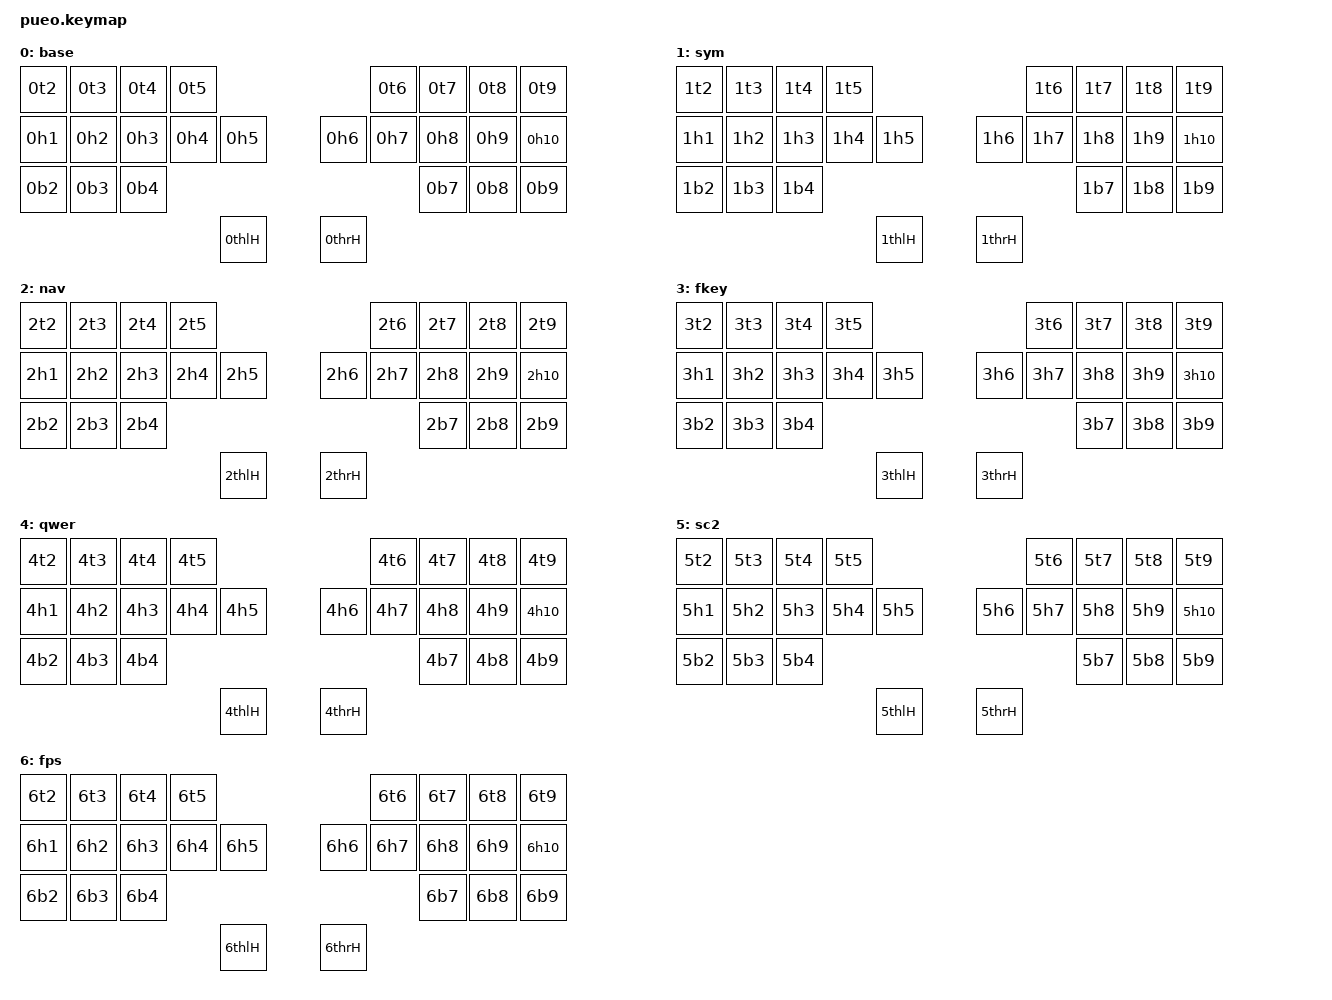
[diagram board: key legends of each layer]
#include "fingermap.h"

/ { 
behaviors { // -----------------------------------------------------------------------------------------------
        hml: home_row_mod_l { 		hold-trigger-key-positions = < 0 1 2 3 8 9 10 11 12 18 19 20 24 >; 		};
		hmr: home_row_mod_r { 		hold-trigger-key-positions = < 4 5 6 7 13 14 15 16 21 22 23 25 >; 	 }; };
// -----------------------------------------------------------------------------------------------------------

keymap { compatible = "zmk,keymap";
		zero 	{ display-name = "base"; // -------------------
		bindings = < _0t2 _0t3 _0t4 _0t5 		_0t6 _0t7 _0t8 _0t9
				_0h1 _0h2 _0h3 _0h4 _0h5 		_0h6 _0h7 _0h8 _0h9 _0h10
				   	 _0b2 _0b3 _0b4       		     _0b7 _0b8 _0b9
				         	   _0thlH	 		     _0thrH 		>; };
		one 	{ display-name = "sym"; // --------------------
		bindings = < _1t2 _1t3 _1t4 _1t5 		_1t6 _1t7 _1t8 _1t9
				_1h1 _1h2 _1h3 _1h4 _1h5 		_1h6 _1h7 _1h8 _1h9 _1h10
				   	 _1b2 _1b3 _1b4       		     _1b7 _1b8 _1b9
				         	   _1thlH	 		     _1thrH 		>; };
		two 	{ display-name = "nav"; // ------------------
		bindings = < _2t2 _2t3 _2t4 _2t5 		_2t6 _2t7 _2t8 _2t9
				_2h1 _2h2 _2h3 _2h4 _2h5 		_2h6 _2h7 _2h8 _2h9 _2h10
				   	 _2b2 _2b3 _2b4           		 _2b7 _2b8 _2b9
				         	   _2thlH	      		 _2thrH 		>; };
		three 	{ display-name = "fkey"; // -------------------
		bindings = < _3t2 _3t3 _3t4 _3t5 		_3t6 _3t7 _3t8 _3t9
				_3h1 _3h2 _3h3 _3h4 _3h5 		_3h6 _3h7 _3h8 _3h9 _3h10
				   	 _3b2 _3b3 _3b4           		 _3b7 _3b8 _3b9
				         	   _3thlH	      		 _3thrH 		>; };
		four 	{ display-name = "qwer"; // ----------------------
		bindings = < _4t2 _4t3 _4t4 _4t5 		_4t6 _4t7 _4t8 _4t9
				_4h1 _4h2 _4h3 _4h4 _4h5 		_4h6 _4h7 _4h8 _4h9 _4h10
				   	 _4b2 _4b3 _4b4           		 _4b7 _4b8 _4b9
				         	   _4thlH	      		 _4thrH 		>; };
		five 	{ display-name = "sc2"; // -----------------
		bindings = < _5t2 _5t3 _5t4 _5t5 		_5t6 _5t7 _5t8 _5t9
				_5h1 _5h2 _5h3 _5h4 _5h5 		_5h6 _5h7 _5h8 _5h9 _5h10
				   	 _5b2 _5b3 _5b4           		 _5b7 _5b8 _5b9
				         	   _5thlH	      		 _5thrH 		>; };
		six 	{ display-name = "fps"; // ------------------------
		bindings = < _6t2 _6t3 _6t4 _6t5 		_6t6 _6t7 _6t8 _6t9
				_6h1 _6h2 _6h3 _6h4 _6h5 		_6h6 _6h7 _6h8 _6h9 _6h10
				   	 _6b2 _6b3 _6b4           		 _6b7 _6b8 _6b9
				         	   _6thlH	      		 _6thrH 	 >; }; };

combos { compatible = "zmk,combos";
        // alphas ----------------------------------------------------------------------------------------------------------------------------------------
		cbo_x 				{ timeout-ms = <40>; 	key-positions = < 	9 18		>; 	bindings = <	&kp X				>;	layers = <	0		>; 	};
		cbo_q 				{ timeout-ms = <40>; 	key-positions = < 	10 19		>; 	bindings = <	&kp Q				>;	layers = <	0		>; 	};
		cbo_p 				{ timeout-ms = <40>; 	key-positions = < 	3 12		>; 	bindings = <	&kp P				>; 	layers = <	0		>; 	};
		cbo_z 				{ timeout-ms = <40>; 	key-positions = < 	4 13		>; 	bindings = <	&kp Z				>;	layers = <	0		>; 	};
		cbo_j 				{ timeout-ms = <40>; 	key-positions = < 	15 22		>; 	bindings = <	&kp J				>;	layers = <	0		>; 	};
		cbo_v 				{ timeout-ms = <40>; 	key-positions = < 	16 23		>; 	bindings = <	&kp V				>;	layers = <	0		>; 	};
		// symbols ---------------------------------------------------------------------------------------------------------------------------------------
		u_cbo_left 			{ timeout-ms = <40>; 	key-positions = < 	8 14		>; 	bindings = <	&uc 0x2190 0x2190	>; 	layers = <	1		>;	};
		u_cbo_up 			{ timeout-ms = <40>; 	key-positions = < 	10 15		>;	bindings = <	&uc 0x2191 0x2191	>; 	layers = <	1		>;	};
		u_cbo_down 			{ timeout-ms = <40>; 	key-positions = < 	9 16		>; 	bindings = <	&uc 0x2193 0x2193	>; 	layers = <	1		>;	};
		u_cbo_right 		{ timeout-ms = <40>; 	key-positions = < 	11 17		>; 	bindings = <	&uc 0x2192 0x2192	>;	layers = <	1		>;	};

		u_cbo_up_down		{ timeout-ms = <40>; 	key-positions = < 	1 6			>; 	bindings = <	&uc 0x2195 0x2195	>; 	layers = <	1		>;	};
		u_cbo_left_right	{ timeout-ms = <40>; 	key-positions = < 	8 17		>; 	bindings = <	&uc 0x2194 0x2194	>; 	layers = <	1		>;	};

		u_cbo_ne 			{ timeout-ms = <40>; 	key-positions = < 	2 7			>; 	bindings = <	&uc 0x2197 0x2197	>; 	layers = <	1		>;	};
		u_cbo_se 			{ timeout-ms = <40>; 	key-positions = < 	20 23		>; 	bindings = <	&uc 0x2198 0x2198	>; 	layers = <	1		>;	};
		u_cbo_sw 			{ timeout-ms = <40>; 	key-positions = < 	18 21		>; 	bindings = <	&uc 0x2199 0x2199	>; 	layers = <	1		>;	};
		u_cbo_nw 			{ timeout-ms = <40>; 	key-positions = < 	0 5			>; 	bindings = <	&uc 0x2196 0x2196	>; 	layers = <	1		>;	};

		u_cbo_skull 		{ timeout-ms = <40>; 	key-positions = < 	3 4 		>; 	bindings = <	&uc 0x2620 0x2620	>;	layers = <	1		>;	};
		u_cbo_frown 		{ timeout-ms = <40>; 	key-positions = < 	12 13 		>; 	bindings = <	&uc 0x2639 0x2639	>;	layers = <	1		>;	};
		// mods ------------------------------------------------------------------------------------------------------------------------------------------
		cbo_ctrl_l			{ timeout-ms = <20>; 	key-positions = < 	0 9			>; 	bindings = <	&sk LCTRL			>; 	layers = <	0 1 2 3	>; 	};
		cbo_gui_l			{ timeout-ms = <20>; 	key-positions = < 	1 10		>; 	bindings = <	&sk LGUI			>; 	layers = <	0 1 2 3	>; 	};
		cbo_shift_l  		{ timeout-ms = <20>; 	key-positions = < 	11 20		>; 	bindings = <	&sk LSHIFT			>;  layers = <	0 1 2 3	>; 	};
		cbo_alt_l			{ timeout-ms = <20>; 	key-positions = < 	3 12		>; 	bindings = <	&sk LALT			>; 	layers = <	0 1 2 3	>; 	};

		cbo_alt_r			{ timeout-ms = <20>; 	key-positions = < 	4 13		>; 	bindings = <	&sk LALT			>; 	layers = <	0 1 2 3	>; 	};
		cbo_shift_r			{ timeout-ms = <20>; 	key-positions = < 	14 21		>; 	bindings = <	&sk RSHIFT			>;  layers = <	0 1 2 3 >; 	};
		cbo_gui_r			{ timeout-ms = <20>; 	key-positions = < 	6 15		>; 	bindings = <	&sk RGUI			>; 	layers = <	0 1 2 3	>; 	};
		cbo_ctrl_r			{ timeout-ms = <20>; 	key-positions = < 	7 16		>; 	bindings = <	&sk RCTRL			>; 	layers = <	0 1 2 3	>; 	};

		cbo_back_l			{ timeout-ms = <20>; 	key-positions = < 	9 11		>; 	bindings = <	&amt LC(BSPC) BSPC	>; 	layers = <	0 1 2	>; 	};
		cbo_del_l			{ timeout-ms = <20>; 	key-positions = <	10 11		>; 	bindings = <	&amt LC(DEL) DEL	>; 	layers = <	0 1 2	>; 	};
		cbo_tab_l			{ timeout-ms = <20>; 	key-positions = <	0 2			>; 	bindings = <	&tabmt 0 TAB		>;	layers = <	0 1 2	>; 	};
		cbo_esc_l			{ timeout-ms = <20>; 	key-positions = < 	0 1 2		>; 	bindings = <	&amt LC(ESC) ESC	>;	layers = <	0 1 2	>; 	};
		cbo_enter_l			{ timeout-ms = <20>; 	key-positions = <	9 10		>; 	bindings = <	&amt LS(RET) RET	>; 	layers = <	0 1 2	>; 	};

		cbo_back_r			{ timeout-ms = <20>; 	key-positions = < 	14 15		>; 	bindings = <	&amt RC(BSPC) BSPC	>; 	layers = <	0 1 2	>; 	};
		cbo_del_r			{ timeout-ms = <20>; 	key-positions = < 	14 16		>; 	bindings = <	&amt RC(DEL) DEL	>; 	layers = <	0 1 2	>; 	};
		cbo_tab_r			{ timeout-ms = <20>; 	key-positions = < 	5 7			>;	bindings = <	&tabmt 0 TAB		>; 	layers = <	0 1 2	>; 	};
		cbo_esc_r			{ timeout-ms = <20>; 	key-positions = < 	5 6 7		>; 	bindings = <	&amt RC(ESC) ESC	>; 	layers = <	0 1 2	>; 	};
		cbo_enter_r			{ timeout-ms = <20>; 	key-positions = < 	15 16		>; 	bindings = <	&amt RS(RET) RET	>; 	layers = <	0 1 2	>; 	};
		// arrows ----------------------------------------------------------------------------------------------------------------------------------------
		cbo_left 			{ timeout-ms = <40>; 	key-positions = < 	8 14		>; 	bindings = <	&amt LC(LEFT)  LEFT	>; 	layers = <	0		>;	};
		cbo_up 				{ timeout-ms = <40>; 	key-positions = < 	10 15		>;	bindings = <	&amt LC(UP)    UP	>; 	layers = <	0		>;	};
		cbo_down 			{ timeout-ms = <40>; 	key-positions = < 	9 16		>;	bindings = <	&amt LC(DOWN)  DOWN	>; 	layers = <	0		>;	};
		cbo_right 			{ timeout-ms = <40>; 	key-positions = < 	11 17		>; 	bindings = <	&amt LC(RIGHT) RIGHT>;	layers = <	0		>;	};
		// layers ----------------------------------------------------------------------------------------------------------------------------------------
		cbo_default 		{ timeout-ms = <40>;	key-positions = < 	10 11 14 15	>;	bindings = <	&to 0				>; 							};
		cbo_default_l 		{ timeout-ms = <40>;	key-positions = < 	0 1 2 8 	>;	bindings = <	&to 0				>; 	layers = <	4 5 6	>;	};
		cbo_fps 			{ timeout-ms = <40>; 	key-positions = < 	9 10 11		>; 	bindings = <	&to 6				>; 							};
		cbo_qwer			{ timeout-ms = <40>; 	key-positions = < 	8 9 11 19	>; 	bindings = <	&to 4				>; 							};
		cbo_minecraft		{ timeout-ms = <40>; 	key-positions = < 	1 8 9 11	>; 	bindings = <	&to 5				>; 							};
		
		cbo_fkeys_l			{ timeout-ms = <40>; 	key-positions = < 	8 12		>; 	bindings = <	&sl 3				>; 	layers = <	0 1 2	>; 	};
		cbo_fkeys_r 		{ timeout-ms = <40>; 	key-positions = < 	13 17		>; 	bindings = <	&sl 3				>; 	layers = <	0 1 2	>; 	};
		// special ---------------------------------------------------------------------------------------------------------------------------------------
		cbo_numword 		{ timeout-ms = <20>; 	key-positions = < 	8 11		>; 	bindings = <	&num_word 1			>;  layers = <	0 1 2	>; 	};
		cbo_capsword 		{ timeout-ms = <20>; 	key-positions = < 	14 17		>; 	bindings = <	&cmt CAPS 0			>;  layers = <	0 1 2	>; 	};
		// game ------------------------------------------------------------------------------------------------------------------------------------------
		g_cbo_tab 			{ timeout-ms = <50>; 	key-positions = < 	0 2			>; 	bindings = <	&kp TAB				>; 	layers = <	4 5 6	>; 	};
		g_cbo_esc 			{ timeout-ms = <50>; 	key-positions = < 	0 1 2		>; 	bindings = <	&kp ESC				>; 	layers = <	4 5 6	>; 	};

		sc_cbo_1 			{ timeout-ms = <50>; 	key-positions = < 	0 9			>; 	bindings = <	&amt F1 N1			>; 	layers = <	5   	>; 	};
		sc_cbo_2 			{ timeout-ms = <50>; 	key-positions = < 	1 10		>; 	bindings = <	&amt F2 N2			>; 	layers = <	5   	>; 	};
		sc_cbo_3 			{ timeout-ms = <50>; 	key-positions = < 	2 11		>; 	bindings = <	&amt F3 N3			>; 	layers = <	5   	>; 	};
		sc_cbo_4 			{ timeout-ms = <50>; 	key-positions = < 	3 12		>; 	bindings = <	&amt F4 N4			>; 	layers = <	5   	>; 	};
		sc_cbo_q 			{ timeout-ms = <50>; 	key-positions = < 	9 18		>; 	bindings = <	&kp Q				>; 	layers = <	5   	>; 	};
		sc_cbo_z			{ timeout-ms = <50>; 	key-positions = < 	10 19		>; 	bindings = <	&kp Z				>; 	layers = <	5   	>; 	};
		sc_cbo_b			{ timeout-ms = <50>; 	key-positions = < 	11 20		>; 	bindings = <	&kp B				>; 	layers = <	5   	>; 	};
		sc_cbo_lshift		{ timeout-ms = <50>; 	key-positions = < 	8 24		>; 	bindings = <	&kp LSHIFT			>; 	layers = <	5   	>; 	};

		g_cbo_1 			{ timeout-ms = <75>; 	key-positions = < 	11 20		>; 	bindings = <	&kp N1				>; 	layers = <	6		>; 	};
		g_cbo_2 			{ timeout-ms = <75>; 	key-positions = < 	9 18		>; 	bindings = <	&kp N2				>; 	layers = <	6		>; 	};
		g_cbo_3 			{ timeout-ms = <75>; 	key-positions = < 	10 19		>; 	bindings = <	&kp N3				>; 	layers = <	6		>; 	};
		g_cbo_4 			{ timeout-ms = <50>; 	key-positions = < 	9 10 11		>; 	bindings = <	&kp N4				>; 	layers = <	6		>; 	};
		g_cbo_spsft			{ timeout-ms = <50>; 	key-positions = < 	8 24		>; 	bindings = <	&gamespaceshift		>; 	layers = <	6		>; 	};
		g_cbo_b				{ timeout-ms = <50>; 	key-positions = < 	19 20		>; 	bindings = <	&kp B				>; 	layers = <	6		>; 	};

		g_cbo_lalt 			{ timeout-ms = <50>; 	key-positions = < 	8 24		>; 	bindings = <	&sk LALT 			>; 	layers = <	4  >; }; }; };
